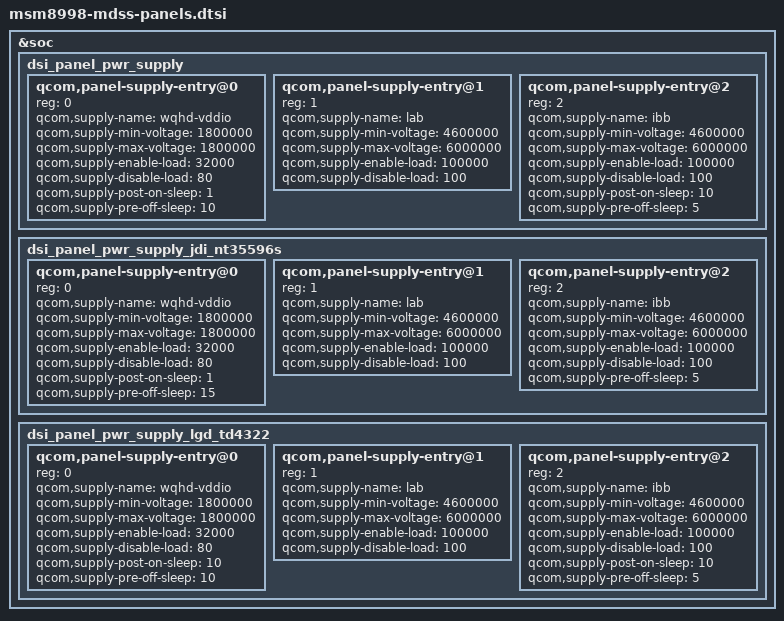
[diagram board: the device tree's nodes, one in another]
/* Copyright (c) 2016-2017, The Linux Foundation. All rights reserved.
 *
 * This program is free software; you can redistribute it and/or modify
 * it under the terms of the GNU General Public License version 2 and
 * only version 2 as published by the Free Software Foundation.
 *
 * This program is distributed in the hope that it will be useful,
 * but WITHOUT ANY WARRANTY; without even the implied warranty of
 * MERCHANTABILITY or FITNESS FOR A PARTICULAR PURPOSE.  See the
 * GNU General Public License for more details.
 */

#include "dsi-panel-jdi-fhd-r63452-cmd.dtsi"
#include "dsi-panel-lgd-fhd-td4322-cmd.dtsi"
#include "dsi-panel-jdi-fhd-nt35596s-video.dtsi"
#include "dsi-panel-jdi-fhd-nt35596s-pro-video.dtsi"

&soc {
	dsi_panel_pwr_supply: dsi_panel_pwr_supply {
		#address-cells = <1>;
		#size-cells = <0>;

		qcom,panel-supply-entry@0 {
			reg = <0>;
			qcom,supply-name = "wqhd-vddio";
			qcom,supply-min-voltage = <1800000>;
			qcom,supply-max-voltage = <1800000>;
			qcom,supply-enable-load = <32000>;
			qcom,supply-disable-load = <80>;
			qcom,supply-post-on-sleep = <1>;
			qcom,supply-pre-off-sleep = <10>;
		};

		qcom,panel-supply-entry@1 {
			reg = <1>;
			qcom,supply-name = "lab";
			qcom,supply-min-voltage = <4600000>;
			qcom,supply-max-voltage = <6000000>;
			qcom,supply-enable-load = <100000>;
			qcom,supply-disable-load = <100>;
		};

		qcom,panel-supply-entry@2 {
			reg = <2>;
			qcom,supply-name = "ibb";
			qcom,supply-min-voltage = <4600000>;
			qcom,supply-max-voltage = <6000000>;
			qcom,supply-enable-load = <100000>;
			qcom,supply-disable-load = <100>;
			qcom,supply-post-on-sleep = <10>;
			qcom,supply-pre-off-sleep = <5>;
		};
	};
};

&soc {
	dsi_panel_pwr_supply_jdi_nt35596s: dsi_panel_pwr_supply_jdi_nt35596s {
		#address-cells = <1>;
		#size-cells = <0>;

		qcom,panel-supply-entry@0 {
			reg = <0>;
			qcom,supply-name = "wqhd-vddio";
			qcom,supply-min-voltage = <1800000>;
			qcom,supply-max-voltage = <1800000>;
			qcom,supply-enable-load = <32000>;
			qcom,supply-disable-load = <80>;
			qcom,supply-post-on-sleep = <1>;
			qcom,supply-pre-off-sleep = <15>;
		};

		qcom,panel-supply-entry@1 {
			reg = <1>;
			qcom,supply-name = "lab";
			qcom,supply-min-voltage = <4600000>;
			qcom,supply-max-voltage = <6000000>;
			qcom,supply-enable-load = <100000>;
			qcom,supply-disable-load = <100>;
		};

		qcom,panel-supply-entry@2 {
			reg = <2>;
			qcom,supply-name = "ibb";
			qcom,supply-min-voltage = <4600000>;
			qcom,supply-max-voltage = <6000000>;
			qcom,supply-enable-load = <100000>;
			qcom,supply-disable-load = <100>;
			qcom,supply-pre-off-sleep = <5>;
		};
	};
};

&soc {
	dsi_panel_pwr_supply_lgd_td4322: dsi_panel_pwr_supply_lgd_td4322 {
		#address-cells = <1>;
		#size-cells = <0>;

		qcom,panel-supply-entry@0 {
			reg = <0>;
			qcom,supply-name = "wqhd-vddio";
			qcom,supply-min-voltage = <1800000>;
			qcom,supply-max-voltage = <1800000>;
			qcom,supply-enable-load = <32000>;
			qcom,supply-disable-load = <80>;
			qcom,supply-post-on-sleep = <10>;
			qcom,supply-pre-off-sleep = <10>;
		};

		qcom,panel-supply-entry@1 {
			reg = <1>;
			qcom,supply-name = "lab";
			qcom,supply-min-voltage = <4600000>;
			qcom,supply-max-voltage = <6000000>;
			qcom,supply-enable-load = <100000>;
			qcom,supply-disable-load = <100>;
		};

		qcom,panel-supply-entry@2 {
			reg = <2>;
			qcom,supply-name = "ibb";
			qcom,supply-min-voltage = <4600000>;
			qcom,supply-max-voltage = <6000000>;
			qcom,supply-enable-load = <100000>;
			qcom,supply-disable-load = <100>;
			qcom,supply-post-on-sleep = <10>;
			qcom,supply-pre-off-sleep = <5>;
		};
	};
};
